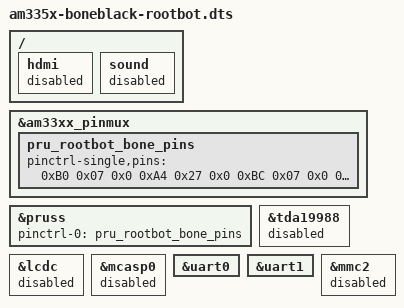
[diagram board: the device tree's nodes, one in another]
/*
 * Copyright (C) 2017 Texas Instruments Incorporated - http://www.ti.com/
 *
 * This program is free software; you can redistribute it and/or modify
 * it under the terms of the GNU General Public License version 2 as
 * published by the Free Software Foundation.
 */

#include "am335x-boneblack.dts"

&am33xx_pinmux {
	pru_rootbot_bone_pins: pru_rootbot_bone_pins {
		pinctrl-single,pins = <
			/* HCSR04 sonic range sensors!  */
			/* FL */
			0xB0 0x07 0x0 /* Trigger: P8_41 gpio2[10] pin44 GPIO74 out pulldown Mode: 7 */
			0xA4 0x27 0x0 /* Echo: P8_46 gpio2[7] pin41 GPIO71 in pulldown Mode: 7 */
			
			/* FC */
			0xBC 0x07 0x0 /* Trigger: P8_40 gpio2[13] pin47 GPIO77 out pulldown Mode: 7 */
			0xA0 0x27 0x0 /* Echo: P8_45 gpio2[6] pin40 GPIO70 in pulldown Mode: 7 */
			
			/* FR */
			0xB8 0x07 0x0 /* Trigger: P8_39 gpio2[12] pin46 GPIO76 out pulldown Mode: 7 */
			/* When connected P8_44 prevents BBB from booting!! Therefore use P8_32 */
			0xDC 0x27 0x0 /* Echo: P8_32 gpio0[11] pin55 GPIO11 in pulldown Mode: 7 */
			
			/* RL */
			0xC4 0x07 0x0 /* Trigger: P8_38 gpio2[15] pin49 GPIO79 out pulldown Mode: 7 */
			0xA8 0x27 0x0 /* Echo: P8_43 gpio2[8] pin42 GPIO72 in pulldown Mode: 7 */
			
			/* RR */
			0xC0 0x07 0x0 /* Trigger: P8_37 gpio2[14] pin48 GPIO78 out pulldown Mode: 7 */
			0xB4 0x27 0x0 /* Echo: P8_42 gpio2[11] pin45 GPIO75 in pulldown Mode: 7 */

			/* LCD st7565 panel pins */
			0x34 0x07 0x0 /* CS: P8_11 gpio1[13] pin 13 GPIO23 out floating Mode: 7 */
			0x8C 0x07 0x0 /* RST: P8_18 gpio2[1] pin 35 GPIO65 out floating Mode: 7 */
			0x24 0x07 0x0 /* AP: P8_13 gpio0[23] pin 9 GPIO23 out floating Mode: 7 */
			0x28 0x07 0x0 /* A0: P8_14 gpio0[26] pin 10 GPIO26 out floating Mode: 7 */
			0x3C 0x07 0x0 /* CLK: P8_15 gpio1[15] pin 15 GPIO47 out floating Mode: 7 */
			0x38 0x07 0x0 /* SI: P8_16 gpio1[14] pin 14 GPIO46 out floating Mode: 7 */

			/* Stepper motor Left */
			0xE0 0x07 0x0 /* North: P8_27 gpio2[22] pin 56 GPIO86 out floating Mode: 7 */
			0xE8 0x07 0x0 /* East: P8_28 gpio2[24] pin 58 GPIO88 out floating Mode: 7 */
			0xE4 0x07 0x0 /* South: P8_29 gpio2[23] pin 57 GPIO87 out floating Mode: 7 */
			0xEC 0x07 0x0 /* West: P8_30 gpio2[25] pin 59 GPIO89 out floating Mode: 7 */

			/* Stepper motor Right */
			0xD4 0x07 0x0 /* North: P8_33 gpio0[9] pin 53 GPIO9 out floating Mode: 7 */
			0xCC 0x07 0x0 /* East: P8_34 gpio2[17] pin 51 GPIO81 out floating Mode: 7 */
			0xD0 0x07 0x0 /* South: P8_35 gpio0[8] pin 52 GPIO8 out floating Mode: 7 */
			0xC8 0x07 0x0 /* West: P8_36 gpio2[16] pin 50 GPIO80 out floating Mode: 7 */
		>;
	};
};

&pruss {
        pinctrl-names = "default";
	pinctrl-0 = <&pru_rootbot_bone_pins>;
};

/* Reserve 256kB DDR memory for the ping/pong buffers */
/{	
	/*reserved-memory {
		#address-cells = <1>;
		#size-cells = <1>;
		ranges;
		
		pruadc_reserved: pruadc_reserved@0x9ffc0000 {
			reg = <0x9ffc0000 0x00040000>;
			no-map;
			status = "okay";
		};
	};
*/
	hdmi {
		status = "disabled";
	};
};

/* Disable the following nodes due to pin mux conflicts with PRU signals needed */
&tda19988 {
	status = "disabled";
};

&lcdc {
	status = "disabled";
};

&mcasp0 {
	status = "disabled";
};

&uart0 {
	status = "okay";
};

&uart1 {
	status = "okay";
};

&mmc2 {
	status = "disabled";
};

/{
	sound {
		status = "disabled";
	};
};

